# ATSAML11E15A register map
Vendor: Microchip Technology; Series: SAML11; File version: 0
CPU: CM23 r0p0, little endian, MPU, no FPU, 2 interrupt priority bits, 45 interrupts
Registers are 32-bit, read-write, reset 0x0 unless marked. A register's access mark holds for its fields unless they carry their own. Offsets are from the block's base; [hi:lo] are bit positions.

## PAC — Peripheral Access Controller
Base 0x40000000
Same registers: PAC_SEC 0x40000200
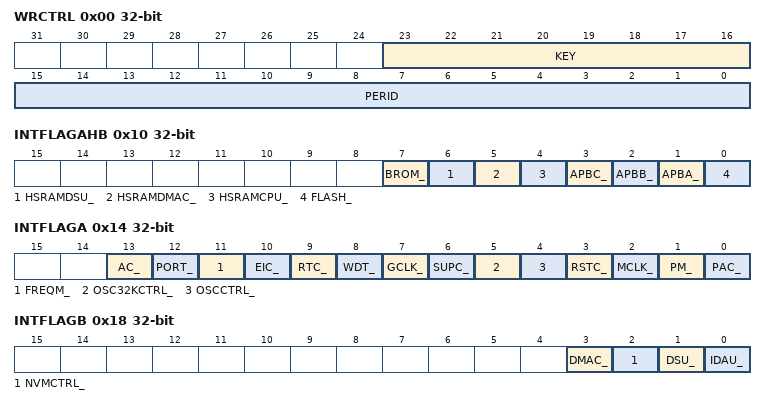
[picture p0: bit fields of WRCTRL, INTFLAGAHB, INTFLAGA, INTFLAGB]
0x00 WRCTRL — Write control
  [23:16] KEY — Peripheral access control key
    0=OFF (No action); 1=CLEAR (Clear protection); 2=SET (Set protection); 3=LOCK (Set and lock protection)
  [15:0] PERID — Peripheral identifier
0x04 EVCTRL 8-bit — Event control
  [0] ERREO — Peripheral acess error event output
0x08 INTENCLR 8-bit write-1-clears — Interrupt enable clear
  [0] ERR — Peripheral access error interrupt disable
0x09 INTENSET 8-bit write-1-sets — Interrupt enable set
  [0] ERR — Peripheral access error interrupt enable
0x10 INTFLAGAHB write-1-clears — Bridge interrupt flag status
  [7] BROM_
  [6] HSRAMDSU_
  [5] HSRAMDMAC_
  [4] HSRAMCPU_
  [3] APBC_ — AHB-APB Bridge C
  [2] APBB_ — AHB-APB Bridge B
  [1] APBA_ — AHB-APB Bridge A
  [0] FLASH_
0x14 INTFLAGA write-1-clears — Peripheral interrupt flag status - Bridge A
  [13] AC_, [12] PORT_, [11] FREQM_, [10] EIC_, [9] RTC_, [8] WDT_, [7] GCLK_, [6] SUPC_, [5] OSC32KCTRL_, [4] OSCCTRL_, [3] RSTC_, [2] MCLK_, [1] PM_, [0] PAC_
0x18 INTFLAGB write-1-clears — Peripheral interrupt flag status - Bridge B
  [3] DMAC_, [2] NVMCTRL_, [1] DSU_, [0] IDAU_
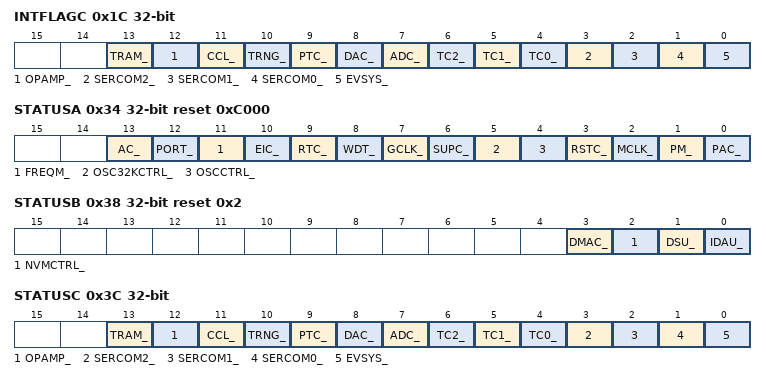
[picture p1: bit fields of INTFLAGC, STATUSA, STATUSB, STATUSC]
0x1C INTFLAGC write-1-clears — Peripheral interrupt flag status - Bridge C
  [13] TRAM_, [12] OPAMP_, [11] CCL_, [10] TRNG_, [9] PTC_, [8] DAC_, [7] ADC_, [6] TC2_, [5] TC1_, [4] TC0_, [3] SERCOM2_, [2] SERCOM1_, [1] SERCOM0_, [0] EVSYS_
0x34 STATUSA ro reset 0xC000 — Peripheral write protection status - Bridge A
  [13] AC_ — AC APB Protect Enable
  [12] PORT_ — PORT APB Protect Enable
  [11] FREQM_ — FREQM APB Protect Enable
  [10] EIC_ — EIC APB Protect Enable
  [9] RTC_ — RTC APB Protect Enable
  [8] WDT_ — WDT APB Protect Enable
  [7] GCLK_ — GCLK APB Protect Enable
  [6] SUPC_ — SUPC APB Protect Enable
  [5] OSC32KCTRL_ — OSC32KCTRL APB Protect Enable
  [4] OSCCTRL_ — OSCCTRL APB Protect Enable
  [3] RSTC_ — RSTC APB Protect Enable
  [2] MCLK_ — MCLK APB Protect Enable
  [1] PM_ — PM APB Protect Enable
  [0] PAC_ — PAC APB Protect Enable
0x38 STATUSB ro reset 0x2 — Peripheral write protection status - Bridge B
  [3] DMAC_ — DMAC APB Protect Enable
  [2] NVMCTRL_ — NVMCTRL APB Protect Enable
  [1] DSU_ — DSU APB Protect Enable
  [0] IDAU_ — IDAU APB Protect Enable
0x3C STATUSC ro — Peripheral write protection status - Bridge C
  [13] TRAM_ — TRAM APB Protect Enable
  [12] OPAMP_ — OPAMP APB Protect Enable
  [11] CCL_ — CCL APB Protect Enable
  [10] TRNG_ — TRNG APB Protect Enable
  [9] PTC_ — PTC APB Protect Enable
  [8] DAC_ — DAC APB Protect Enable
  [7] ADC_ — ADC APB Protect Enable
  [6] TC2_ — TC2 APB Protect Enable
  [5] TC1_ — TC1 APB Protect Enable
  [4] TC0_ — TC0 APB Protect Enable
  [3] SERCOM2_ — SERCOM2 APB Protect Enable
  [2] SERCOM1_ — SERCOM1 APB Protect Enable
  [1] SERCOM0_ — SERCOM0 APB Protect Enable
  [0] EVSYS_ — EVSYS APB Protect Enable
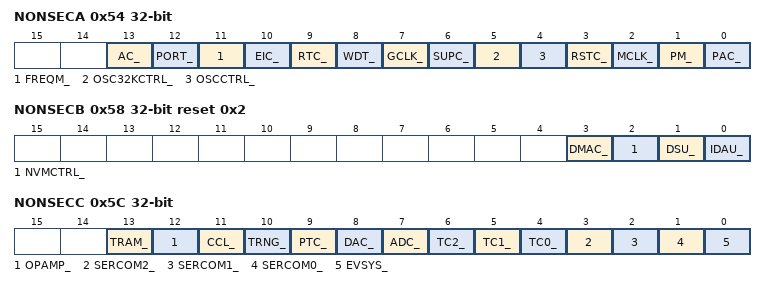
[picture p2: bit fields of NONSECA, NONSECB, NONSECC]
0x54 NONSECA ro — Peripheral non-secure status - Bridge A
  [13] AC_ — AC Non-Secure
  [12] PORT_ — PORT Non-Secure
  [11] FREQM_ — FREQM Non-Secure
  [10] EIC_ — EIC Non-Secure
  [9] RTC_ — RTC Non-Secure
  [8] WDT_ — WDT Non-Secure
  [7] GCLK_ — GCLK Non-Secure
  [6] SUPC_ — SUPC Non-Secure
  [5] OSC32KCTRL_ — OSC32KCTRL Non-Secure
  [4] OSCCTRL_ — OSCCTRL Non-Secure
  [3] RSTC_ — RSTC Non-Secure
  [2] MCLK_ — MCLK Non-Secure
  [1] PM_ — PM Non-Secure
  [0] PAC_ — PAC Non-Secure
0x58 NONSECB ro reset 0x2 — Peripheral non-secure status - Bridge B
  [3] DMAC_ — DMAC Non-Secure
  [2] NVMCTRL_ — NVMCTRL Non-Secure
  [1] DSU_ — DSU Non-Secure
  [0] IDAU_ — IDAU Non-Secure
0x5C NONSECC ro — Peripheral non-secure status - Bridge C
  [13] TRAM_ — TRAM Non-Secure
  [12] OPAMP_ — OPAMP Non-Secure
  [11] CCL_ — CCL Non-Secure
  [10] TRNG_ — TRNG Non-Secure
  [9] PTC_ — PTC Non-Secure
  [8] DAC_ — DAC Non-Secure
  [7] ADC_ — ADC Non-Secure
  [6] TC2_ — TC2 Non-Secure
  [5] TC1_ — TC1 Non-Secure
  [4] TC0_ — TC0 Non-Secure
  [3] SERCOM2_ — SERCOM2 Non-Secure
  [2] SERCOM1_ — SERCOM1 Non-Secure
  [1] SERCOM0_ — SERCOM0 Non-Secure
  [0] EVSYS_ — EVSYS Non-Secure
